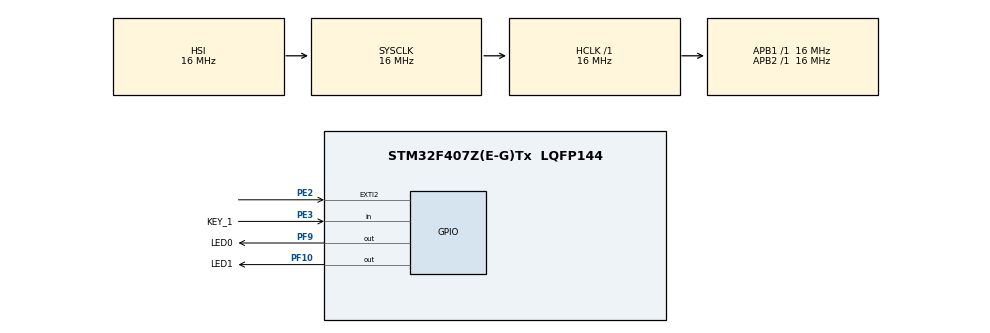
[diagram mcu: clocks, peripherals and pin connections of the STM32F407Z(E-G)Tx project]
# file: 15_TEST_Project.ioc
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Mcu.Family=STM32F4
Mcu.Name=STM32F407Z(E-G)Tx
Mcu.Package=LQFP144
NVIC.EXTI2_IRQn=true\:5\:0\:true\:false\:true\:true\:true
NVIC.PriorityGroup=NVIC_PRIORITYGROUP_4
NVIC.TIM1_UP_TIM10_IRQn=true\:0\:0\:false\:false\:true\:true\:true
NVIC.TIM3_IRQn=true\:0\:0\:false\:false\:true\:true\:true
PE2.GPIO_ModeDefaultEXTI=GPIO_MODE_IT_FALLING
PE2.GPIO_PuPd=GPIO_PULLUP
PE2.Signal=GPXTI2
PE3.GPIO_Label=KEY_1
PE3.GPIO_PuPd=GPIO_PULLUP
PE3.Signal=GPIO_Input
PF10.GPIO_Label=LED1
PF10.GPIO_PuPd=GPIO_NOPULL
PF10.PinState=GPIO_PIN_RESET
PF10.Signal=GPIO_Output
PF9.GPIO_Label=LED0
PF9.GPIO_PuPd=GPIO_NOPULL
PF9.PinState=GPIO_PIN_SET
PF9.Signal=GPIO_Output
ProjectManager.HeapSize=0x200
ProjectManager.StackSize=0x400
ProjectManager.TargetToolchain=MDK-ARM V5
RCC.AHBFreq_Value=16000000
RCC.APB1Freq_Value=16000000
RCC.APB2Freq_Value=16000000
RCC.CortexFreq_Value=16000000
RCC.HSE_VALUE=25000000
RCC.HSI_VALUE=16000000
RCC.LSE_VALUE=32768
RCC.SYSCLKFreq_VALUE=16000000
RCC.VCOOutputFreq_Value=192000000
TIM1.Channel-Output\ Compare1\ No\ Output=TIM_CHANNEL_1
TIM1.Period=999
TIM1.Prescaler=15999
TIM3.Channel-Output\ Compare1\ No\ Output=TIM_CHANNEL_1
TIM3.Period=999
TIM3.Prescaler=15
VP_TIM1_VS_ClockSourceINT.Mode=Internal
VP_TIM1_VS_no_output1.Mode=Output Compare1 No Output
VP_TIM3_VS_ClockSourceINT.Mode=Internal
VP_TIM3_VS_no_output1.Mode=Output Compare1 No Output
board=custom

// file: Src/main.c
/* USER CODE BEGIN Header */
/**
  ******************************************************************************
  * @file           : main.c
  * @brief          : Main program body
  ******************************************************************************
  * @attention
  *
  * <h2><center>&copy; Copyright (c) 2019 STMicroelectronics.
  * All rights reserved.</center></h2>
  *
  * This software component is licensed by ST under BSD 3-Clause license,
  * the "License"; You may not use this file except in compliance with the
  * License. You may obtain a copy of the License at:
  *                        opensource.org/licenses/BSD-3-Clause
  *
  ******************************************************************************
  */
/* USER CODE END Header */

#include "main.h"

TIM_HandleTypeDef htim1;
TIM_HandleTypeDef htim3;

void SystemClock_Config(void);
static void MX_GPIO_Init(void);
static void MX_TIM1_Init(void);
static void MX_TIM3_Init(void);

int main(void)
{

  /* MCU Configuration--------------------------------------------------------*/

  /* Reset of all peripherals, Initializes the Flash interface and the Systick. */
  HAL_Init();

  /* Configure the system clock */
  SystemClock_Config();

  /* Initialize all configured peripherals */
  MX_GPIO_Init();
  MX_TIM1_Init();
  MX_TIM3_Init();
  /* USER CODE BEGIN 2 */
  HAL_TIM_Base_Start_IT(&htim1);
   HAL_TIM_Base_Start_IT(&htim3);
  /* USER CODE END 2 */

  /* Infinite loop */
  while (1)
  {

    /* USER CODE BEGIN 3 */

//	    HAL_GPIO_WritePin(LED0_GPIO_Port, LED0_Pin, GPIO_PIN_RESET);
//        HAL_GPIO_WritePin(LED1_GPIO_Port, LED1_Pin, GPIO_PIN_SET);
//        HAL_GPIO_TogglePin(LED1_GPIO_Port,  LED1_Pin);
//		HAL_Delay(1000);
//        HAL_GPIO_TogglePin(LED0_GPIO_Port,  LED0_Pin);
//		HAL_Delay(200);
  }
  /* USER CODE END 3 */
}

void SystemClock_Config(void)
{
  RCC_OscInitTypeDef RCC_OscInitStruct = {0};
  RCC_ClkInitTypeDef RCC_ClkInitStruct = {0};

  /** Configure the main internal regulator output voltage
  */
  __HAL_RCC_PWR_CLK_ENABLE();
  __HAL_PWR_VOLTAGESCALING_CONFIG(PWR_REGULATOR_VOLTAGE_SCALE1);
  /** Initializes the CPU, AHB and APB busses clocks
  */
  RCC_OscInitStruct.OscillatorType = RCC_OSCILLATORTYPE_HSI;
  RCC_OscInitStruct.HSIState = RCC_HSI_ON;
  RCC_OscInitStruct.HSICalibrationValue = RCC_HSICALIBRATION_DEFAULT;
  RCC_OscInitStruct.PLL.PLLState = RCC_PLL_NONE;
  if (HAL_RCC_OscConfig(&RCC_OscInitStruct) != HAL_OK)
  {
    Error_Handler();
  }
  /** Initializes the CPU, AHB and APB busses clocks
  */
  RCC_ClkInitStruct.ClockType = RCC_CLOCKTYPE_HCLK|RCC_CLOCKTYPE_SYSCLK
                              |RCC_CLOCKTYPE_PCLK1|RCC_CLOCKTYPE_PCLK2;
  RCC_ClkInitStruct.SYSCLKSource = RCC_SYSCLKSOURCE_HSI;
  RCC_ClkInitStruct.AHBCLKDivider = RCC_SYSCLK_DIV1;
  RCC_ClkInitStruct.APB1CLKDivider = RCC_HCLK_DIV1;
  RCC_ClkInitStruct.APB2CLKDivider = RCC_HCLK_DIV1;

  if (HAL_RCC_ClockConfig(&RCC_ClkInitStruct, FLASH_LATENCY_0) != HAL_OK)
  {
    Error_Handler();
  }
}

static void MX_TIM1_Init(void)
{

  TIM_ClockConfigTypeDef sClockSourceConfig = {0};
  TIM_MasterConfigTypeDef sMasterConfig = {0};
  TIM_OC_InitTypeDef sConfigOC = {0};
  TIM_BreakDeadTimeConfigTypeDef sBreakDeadTimeConfig = {0};

  htim1.Instance = TIM1;
  htim1.Init.Prescaler = 15999;
  htim1.Init.CounterMode = TIM_COUNTERMODE_UP;
  htim1.Init.Period = 999;
  htim1.Init.ClockDivision = TIM_CLOCKDIVISION_DIV1;
  htim1.Init.RepetitionCounter = 0;
  htim1.Init.AutoReloadPreload = TIM_AUTORELOAD_PRELOAD_DISABLE;
  if (HAL_TIM_Base_Init(&htim1) != HAL_OK)
  {
    Error_Handler();
  }
  sClockSourceConfig.ClockSource = TIM_CLOCKSOURCE_INTERNAL;
  if (HAL_TIM_ConfigClockSource(&htim1, &sClockSourceConfig) != HAL_OK)
  {
    Error_Handler();
  }
  if (HAL_TIM_OC_Init(&htim1) != HAL_OK)
  {
    Error_Handler();
  }
  sMasterConfig.MasterOutputTrigger = TIM_TRGO_RESET;
  sMasterConfig.MasterSlaveMode = TIM_MASTERSLAVEMODE_DISABLE;
  if (HAL_TIMEx_MasterConfigSynchronization(&htim1, &sMasterConfig) != HAL_OK)
  {
    Error_Handler();
  }
  sConfigOC.OCMode = TIM_OCMODE_TIMING;
  sConfigOC.Pulse = 0;
  sConfigOC.OCPolarity = TIM_OCPOLARITY_HIGH;
  sConfigOC.OCNPolarity = TIM_OCNPOLARITY_HIGH;
  sConfigOC.OCFastMode = TIM_OCFAST_DISABLE;
  sConfigOC.OCIdleState = TIM_OCIDLESTATE_RESET;
  sConfigOC.OCNIdleState = TIM_OCNIDLESTATE_RESET;
  if (HAL_TIM_OC_ConfigChannel(&htim1, &sConfigOC, TIM_CHANNEL_1) != HAL_OK)
  {
    Error_Handler();
  }
  sBreakDeadTimeConfig.OffStateRunMode = TIM_OSSR_DISABLE;
  sBreakDeadTimeConfig.OffStateIDLEMode = TIM_OSSI_DISABLE;
  sBreakDeadTimeConfig.LockLevel = TIM_LOCKLEVEL_OFF;
  sBreakDeadTimeConfig.DeadTime = 0;
  sBreakDeadTimeConfig.BreakState = TIM_BREAK_DISABLE;
  sBreakDeadTimeConfig.BreakPolarity = TIM_BREAKPOLARITY_HIGH;
  sBreakDeadTimeConfig.AutomaticOutput = TIM_AUTOMATICOUTPUT_DISABLE;
  if (HAL_TIMEx_ConfigBreakDeadTime(&htim1, &sBreakDeadTimeConfig) != HAL_OK)
  {
    Error_Handler();
  }

}

static void MX_TIM3_Init(void)
{

  TIM_ClockConfigTypeDef sClockSourceConfig = {0};
  TIM_MasterConfigTypeDef sMasterConfig = {0};
  TIM_OC_InitTypeDef sConfigOC = {0};

  htim3.Instance = TIM3;
  htim3.Init.Prescaler = 15;
  htim3.Init.CounterMode = TIM_COUNTERMODE_UP;
  htim3.Init.Period = 999;
  htim3.Init.ClockDivision = TIM_CLOCKDIVISION_DIV1;
  htim3.Init.AutoReloadPreload = TIM_AUTORELOAD_PRELOAD_DISABLE;
  if (HAL_TIM_Base_Init(&htim3) != HAL_OK)
  {
    Error_Handler();
  }
  sClockSourceConfig.ClockSource = TIM_CLOCKSOURCE_INTERNAL;
  if (HAL_TIM_ConfigClockSource(&htim3, &sClockSourceConfig) != HAL_OK)
  {
    Error_Handler();
  }
  if (HAL_TIM_OC_Init(&htim3) != HAL_OK)
  {
    Error_Handler();
  }
  sMasterConfig.MasterOutputTrigger = TIM_TRGO_RESET;
  sMasterConfig.MasterSlaveMode = TIM_MASTERSLAVEMODE_DISABLE;
  if (HAL_TIMEx_MasterConfigSynchronization(&htim3, &sMasterConfig) != HAL_OK)
  {
    Error_Handler();
  }
  sConfigOC.OCMode = TIM_OCMODE_TIMING;
  sConfigOC.Pulse = 0;
  sConfigOC.OCPolarity = TIM_OCPOLARITY_HIGH;
  sConfigOC.OCFastMode = TIM_OCFAST_DISABLE;
  if (HAL_TIM_OC_ConfigChannel(&htim3, &sConfigOC, TIM_CHANNEL_1) != HAL_OK)
  {
    Error_Handler();
  }

}

static void MX_GPIO_Init(void)
{
  GPIO_InitTypeDef GPIO_InitStruct = {0};

  /* GPIO Ports Clock Enable */
  __HAL_RCC_GPIOE_CLK_ENABLE();
  __HAL_RCC_GPIOF_CLK_ENABLE();

  /*Configure GPIO pin Output Level */
  HAL_GPIO_WritePin(LED0_GPIO_Port, LED0_Pin, GPIO_PIN_SET);

  /*Configure GPIO pin Output Level */
  HAL_GPIO_WritePin(LED1_GPIO_Port, LED1_Pin, GPIO_PIN_RESET);

  /*Configure GPIO pin : PE2 */
  GPIO_InitStruct.Pin = GPIO_PIN_2;
  GPIO_InitStruct.Mode = GPIO_MODE_IT_FALLING;
  GPIO_InitStruct.Pull = GPIO_PULLUP;
  HAL_GPIO_Init(GPIOE, &GPIO_InitStruct);

  /*Configure GPIO pin : KEY_1_Pin */
  GPIO_InitStruct.Pin = KEY_1_Pin;
  GPIO_InitStruct.Mode = GPIO_MODE_INPUT;
  GPIO_InitStruct.Pull = GPIO_PULLUP;
  HAL_GPIO_Init(KEY_1_GPIO_Port, &GPIO_InitStruct);

  /*Configure GPIO pins : LED0_Pin LED1_Pin */
  GPIO_InitStruct.Pin = LED0_Pin|LED1_Pin;
  GPIO_InitStruct.Mode = GPIO_MODE_OUTPUT_PP;
  GPIO_InitStruct.Pull = GPIO_NOPULL;
  GPIO_InitStruct.Speed = GPIO_SPEED_FREQ_LOW;
  HAL_GPIO_Init(GPIOF, &GPIO_InitStruct);

  /* EXTI interrupt init*/
  HAL_NVIC_SetPriority(EXTI2_IRQn, 5, 0);
  HAL_NVIC_EnableIRQ(EXTI2_IRQn);

}

/* USER CODE BEGIN 4 */
void HAL_GPIO_EXTI_Callback(uint16_t GPIO_Pin)
{
//	if (GPIO_Pin == GPIO_PIN_2)
//	{
//		HAL_Delay(10);
		if (GPIO_Pin == GPIO_PIN_2)
		{
			while(HAL_GPIO_ReadPin(GPIOE, GPIO_PIN_2) == 0);

			HAL_GPIO_TogglePin(LED0_GPIO_Port,  LED0_Pin);
		}
//	}

}
void HAL_TIM_PeriodElapsedCallback(TIM_HandleTypeDef *htim)
{
	if (htim == &htim1)
	{
		HAL_GPIO_TogglePin(LED1_GPIO_Port,  LED1_Pin);
	}
	else if (htim == &htim3)
	{
		if (HAL_GPIO_ReadPin(KEY_1_GPIO_Port, KEY_1_Pin) == 0)
		{
			while(HAL_GPIO_ReadPin(KEY_1_GPIO_Port, KEY_1_Pin) == 1);
			HAL_GPIO_TogglePin(LED0_GPIO_Port,  LED0_Pin);
		}
		//HAL_GPIO_TogglePin(LED0_GPIO_Port,  LED0_Pin);

	}
}
/* USER CODE END 4 */

void Error_Handler(void)
{
}

/************************ (C) COPYRIGHT STMicroelectronics *****END OF FILE****/
